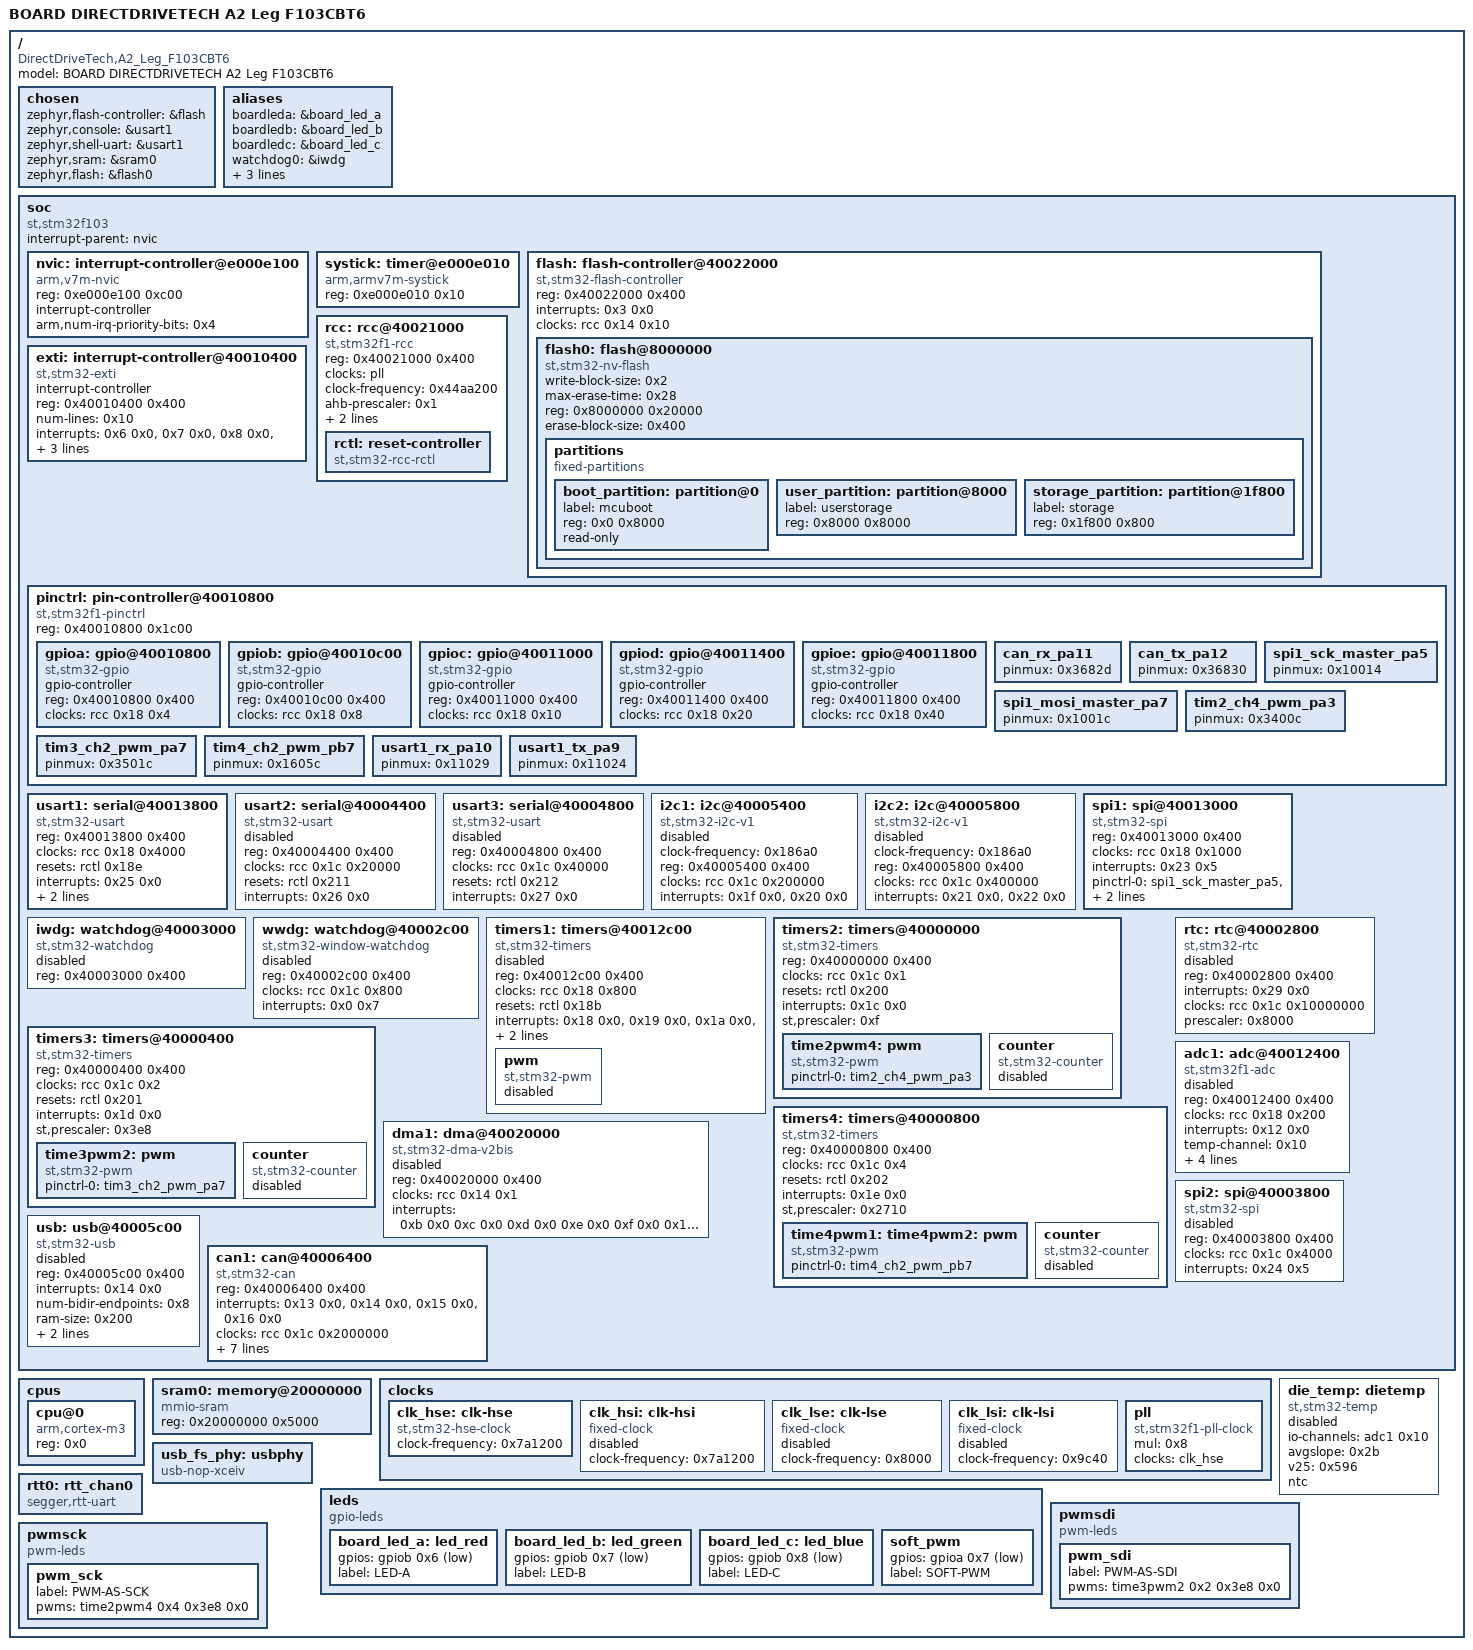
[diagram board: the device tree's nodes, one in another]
/dts-v1/;

/ {
	#address-cells = < 0x1 >;
	#size-cells = < 0x1 >;
	model = "BOARD DIRECTDRIVETECH A2 Leg F103CBT6";
	compatible = "DirectDriveTech,A2_Leg_F103CBT6";
	chosen {
		zephyr,flash-controller = &flash;
		zephyr,console = &usart1;
		zephyr,shell-uart = &usart1;
		zephyr,sram = &sram0;
		zephyr,flash = &flash0;
	};
	aliases {
		boardleda = &board_led_a;
		boardledb = &board_led_b;
		boardledc = &board_led_c;
		watchdog0 = &iwdg;
		pwmassck = &pwm_sck;
		pwmassdi = &pwm_sdi;
		softpwm = &soft_pwm;
	};
	soc {
		#address-cells = < 0x1 >;
		#size-cells = < 0x1 >;
		compatible = "st,stm32f103", "st,stm32f1", "simple-bus";
		interrupt-parent = < &nvic >;
		ranges;
		nvic: interrupt-controller@e000e100 {
			#address-cells = < 0x1 >;
			compatible = "arm,v7m-nvic";
			reg = < 0xe000e100 0xc00 >;
			interrupt-controller;
			#interrupt-cells = < 0x2 >;
			arm,num-irq-priority-bits = < 0x4 >;
			phandle = < 0x1 >;
		};
		systick: timer@e000e010 {
			compatible = "arm,armv7m-systick";
			reg = < 0xe000e010 0x10 >;
		};
		flash: flash-controller@40022000 {
			compatible = "st,stm32-flash-controller", "st,stm32f1-flash-controller";
			reg = < 0x40022000 0x400 >;
			interrupts = < 0x3 0x0 >;
			clocks = < &rcc 0x14 0x10 >;
			#address-cells = < 0x1 >;
			#size-cells = < 0x1 >;
			flash0: flash@8000000 {
				compatible = "st,stm32-nv-flash", "soc-nv-flash";
				write-block-size = < 0x2 >;
				max-erase-time = < 0x28 >;
				reg = < 0x8000000 0x20000 >;
				erase-block-size = < 0x400 >;
				partitions {
					compatible = "fixed-partitions";
					#address-cells = < 0x1 >;
					#size-cells = < 0x1 >;
					boot_partition: partition@0 {
						label = "mcuboot";
						reg = < 0x0 0x8000 >;
						read-only;
					};
					user_partition: partition@8000 {
						label = "userstorage";
						reg = < 0x8000 0x8000 >;
					};
					storage_partition: partition@1f800 {
						label = "storage";
						reg = < 0x1f800 0x800 >;
					};
				};
			};
		};
		rcc: rcc@40021000 {
			compatible = "st,stm32f1-rcc";
			#clock-cells = < 0x2 >;
			reg = < 0x40021000 0x400 >;
			clocks = < &pll >;
			clock-frequency = < 0x44aa200 >;
			ahb-prescaler = < 0x1 >;
			apb1-prescaler = < 0x2 >;
			apb2-prescaler = < 0x2 >;
			phandle = < 0x2 >;
			rctl: reset-controller {
				compatible = "st,stm32-rcc-rctl";
				#reset-cells = < 0x1 >;
				phandle = < 0x4 >;
			};
		};
		exti: interrupt-controller@40010400 {
			compatible = "st,stm32-exti";
			interrupt-controller;
			#interrupt-cells = < 0x1 >;
			#address-cells = < 0x1 >;
			reg = < 0x40010400 0x400 >;
			num-lines = < 0x10 >;
			interrupts = < 0x6 0x0 >, < 0x7 0x0 >, < 0x8 0x0 >, < 0x9 0x0 >, < 0xa 0x0 >, < 0x17 0x0 >, < 0x28 0x0 >;
			interrupt-names = "line0", "line1", "line2", "line3", "line4", "line5-9", "line10-15";
			line-ranges = < 0x0 0x1 >, < 0x1 0x1 >, < 0x2 0x1 >, < 0x3 0x1 >, < 0x4 0x1 >, < 0x5 0x5 >, < 0xa 0x6 >;
		};
		pinctrl: pin-controller@40010800 {
			compatible = "st,stm32f1-pinctrl";
			#address-cells = < 0x1 >;
			#size-cells = < 0x1 >;
			reg = < 0x40010800 0x1c00 >;
			gpioa: gpio@40010800 {
				compatible = "st,stm32-gpio";
				gpio-controller;
				#gpio-cells = < 0x2 >;
				reg = < 0x40010800 0x400 >;
				clocks = < &rcc 0x18 0x4 >;
				phandle = < 0x9 >;
			};
			gpiob: gpio@40010c00 {
				compatible = "st,stm32-gpio";
				gpio-controller;
				#gpio-cells = < 0x2 >;
				reg = < 0x40010c00 0x400 >;
				clocks = < &rcc 0x18 0x8 >;
				phandle = < 0x12 >;
			};
			gpioc: gpio@40011000 {
				compatible = "st,stm32-gpio";
				gpio-controller;
				#gpio-cells = < 0x2 >;
				reg = < 0x40011000 0x400 >;
				clocks = < &rcc 0x18 0x10 >;
			};
			gpiod: gpio@40011400 {
				compatible = "st,stm32-gpio";
				gpio-controller;
				#gpio-cells = < 0x2 >;
				reg = < 0x40011400 0x400 >;
				clocks = < &rcc 0x18 0x20 >;
			};
			gpioe: gpio@40011800 {
				compatible = "st,stm32-gpio";
				gpio-controller;
				#gpio-cells = < 0x2 >;
				reg = < 0x40011800 0x400 >;
				clocks = < &rcc 0x18 0x40 >;
			};
			can_rx_pa11: can_rx_pa11 {
				pinmux = < 0x3682d >;
				phandle = < 0xe >;
			};
			can_tx_pa12: can_tx_pa12 {
				pinmux = < 0x36830 >;
				phandle = < 0xf >;
			};
			spi1_mosi_master_pa7: spi1_mosi_master_pa7 {
				pinmux = < 0x1001c >;
				phandle = < 0x8 >;
			};
			spi1_sck_master_pa5: spi1_sck_master_pa5 {
				pinmux = < 0x10014 >;
				phandle = < 0x7 >;
			};
			tim2_ch4_pwm_pa3: tim2_ch4_pwm_pa3 {
				pinmux = < 0x3400c >;
				phandle = < 0xa >;
			};
			tim3_ch2_pwm_pa7: tim3_ch2_pwm_pa7 {
				pinmux = < 0x3501c >;
				phandle = < 0xb >;
			};
			tim4_ch2_pwm_pb7: tim4_ch2_pwm_pb7 {
				pinmux = < 0x1605c >;
				phandle = < 0xc >;
			};
			usart1_rx_pa10: usart1_rx_pa10 {
				pinmux = < 0x11029 >;
				phandle = < 0x6 >;
			};
			usart1_tx_pa9: usart1_tx_pa9 {
				pinmux = < 0x11024 >;
				phandle = < 0x5 >;
			};
		};
		usart1: serial@40013800 {
			compatible = "st,stm32-usart", "st,stm32-uart";
			reg = < 0x40013800 0x400 >;
			clocks = < &rcc 0x18 0x4000 >;
			resets = < &rctl 0x18e >;
			interrupts = < 0x25 0x0 >;
			status = "okay";
			pinctrl-0 = < &usart1_tx_pa9 &usart1_rx_pa10 >;
			pinctrl-names = "default";
			current-speed = < 0x70800 >;
		};
		usart2: serial@40004400 {
			compatible = "st,stm32-usart", "st,stm32-uart";
			reg = < 0x40004400 0x400 >;
			clocks = < &rcc 0x1c 0x20000 >;
			resets = < &rctl 0x211 >;
			interrupts = < 0x26 0x0 >;
			status = "disabled";
		};
		usart3: serial@40004800 {
			compatible = "st,stm32-usart", "st,stm32-uart";
			reg = < 0x40004800 0x400 >;
			clocks = < &rcc 0x1c 0x40000 >;
			resets = < &rctl 0x212 >;
			interrupts = < 0x27 0x0 >;
			status = "disabled";
		};
		i2c1: i2c@40005400 {
			compatible = "st,stm32-i2c-v1";
			clock-frequency = < 0x186a0 >;
			#address-cells = < 0x1 >;
			#size-cells = < 0x0 >;
			reg = < 0x40005400 0x400 >;
			clocks = < &rcc 0x1c 0x200000 >;
			interrupts = < 0x1f 0x0 >, < 0x20 0x0 >;
			interrupt-names = "event", "error";
			status = "disabled";
		};
		i2c2: i2c@40005800 {
			compatible = "st,stm32-i2c-v1";
			clock-frequency = < 0x186a0 >;
			#address-cells = < 0x1 >;
			#size-cells = < 0x0 >;
			reg = < 0x40005800 0x400 >;
			clocks = < &rcc 0x1c 0x400000 >;
			interrupts = < 0x21 0x0 >, < 0x22 0x0 >;
			interrupt-names = "event", "error";
			status = "disabled";
		};
		spi1: spi@40013000 {
			compatible = "st,stm32-spi";
			#address-cells = < 0x1 >;
			#size-cells = < 0x0 >;
			reg = < 0x40013000 0x400 >;
			clocks = < &rcc 0x18 0x1000 >;
			interrupts = < 0x23 0x5 >;
			status = "okay";
			pinctrl-0 = < &spi1_sck_master_pa5 &spi1_mosi_master_pa7 >;
			cs-gpios = < &gpioa 0x4 0x1 >;
			pinctrl-names = "default";
		};
		iwdg: watchdog@40003000 {
			compatible = "st,stm32-watchdog";
			reg = < 0x40003000 0x400 >;
			status = "disabled";
		};
		wwdg: watchdog@40002c00 {
			compatible = "st,stm32-window-watchdog";
			reg = < 0x40002c00 0x400 >;
			clocks = < &rcc 0x1c 0x800 >;
			interrupts = < 0x0 0x7 >;
			status = "disabled";
		};
		timers1: timers@40012c00 {
			compatible = "st,stm32-timers";
			reg = < 0x40012c00 0x400 >;
			clocks = < &rcc 0x18 0x800 >;
			resets = < &rctl 0x18b >;
			interrupts = < 0x18 0x0 >, < 0x19 0x0 >, < 0x1a 0x0 >, < 0x1b 0x0 >;
			interrupt-names = "brk", "up", "trgcom", "cc";
			st,prescaler = < 0x0 >;
			status = "disabled";
			pwm {
				compatible = "st,stm32-pwm";
				status = "disabled";
				#pwm-cells = < 0x3 >;
			};
		};
		timers2: timers@40000000 {
			compatible = "st,stm32-timers";
			reg = < 0x40000000 0x400 >;
			clocks = < &rcc 0x1c 0x1 >;
			resets = < &rctl 0x200 >;
			interrupts = < 0x1c 0x0 >;
			interrupt-names = "global";
			st,prescaler = < 0xf >;
			status = "okay";
			time2pwm4: pwm {
				compatible = "st,stm32-pwm";
				status = "okay";
				#pwm-cells = < 0x3 >;
				pinctrl-0 = < &tim2_ch4_pwm_pa3 >;
				pinctrl-names = "default";
				phandle = < 0x14 >;
			};
			counter {
				compatible = "st,stm32-counter";
				status = "disabled";
			};
		};
		timers3: timers@40000400 {
			compatible = "st,stm32-timers";
			reg = < 0x40000400 0x400 >;
			clocks = < &rcc 0x1c 0x2 >;
			resets = < &rctl 0x201 >;
			interrupts = < 0x1d 0x0 >;
			interrupt-names = "global";
			st,prescaler = < 0x3e8 >;
			status = "okay";
			time3pwm2: pwm {
				compatible = "st,stm32-pwm";
				status = "okay";
				#pwm-cells = < 0x3 >;
				pinctrl-0 = < &tim3_ch2_pwm_pa7 >;
				pinctrl-names = "default";
				phandle = < 0x13 >;
			};
			counter {
				compatible = "st,stm32-counter";
				status = "disabled";
			};
		};
		timers4: timers@40000800 {
			compatible = "st,stm32-timers";
			reg = < 0x40000800 0x400 >;
			clocks = < &rcc 0x1c 0x4 >;
			resets = < &rctl 0x202 >;
			interrupts = < 0x1e 0x0 >;
			interrupt-names = "global";
			st,prescaler = < 0x2710 >;
			status = "okay";
			time4pwm1: time4pwm2: pwm {
				compatible = "st,stm32-pwm";
				status = "okay";
				#pwm-cells = < 0x3 >;
				pinctrl-0 = < &tim4_ch2_pwm_pb7 >;
				pinctrl-names = "default";
			};
			counter {
				compatible = "st,stm32-counter";
				status = "disabled";
			};
		};
		rtc: rtc@40002800 {
			compatible = "st,stm32-rtc";
			reg = < 0x40002800 0x400 >;
			interrupts = < 0x29 0x0 >;
			clocks = < &rcc 0x1c 0x10000000 >;
			prescaler = < 0x8000 >;
			status = "disabled";
		};
		adc1: adc@40012400 {
			compatible = "st,stm32f1-adc", "st,stm32-adc";
			reg = < 0x40012400 0x400 >;
			clocks = < &rcc 0x18 0x200 >;
			interrupts = < 0x12 0x0 >;
			status = "disabled";
			#io-channel-cells = < 0x1 >;
			temp-channel = < 0x10 >;
			vref-channel = < 0x11 >;
			resolutions = < 0x6000ff >;
			sampling-times = < 0x2 0x8 0xe 0x1d 0x2a 0x38 0x48 0xf0 >;
			phandle = < 0x11 >;
		};
		dma1: dma@40020000 {
			compatible = "st,stm32-dma-v2bis";
			#dma-cells = < 0x2 >;
			reg = < 0x40020000 0x400 >;
			clocks = < &rcc 0x14 0x1 >;
			interrupts = < 0xb 0x0 0xc 0x0 0xd 0x0 0xe 0x0 0xf 0x0 0x10 0x0 0x11 0x0 >;
			status = "disabled";
		};
		spi2: spi@40003800 {
			compatible = "st,stm32-spi";
			#address-cells = < 0x1 >;
			#size-cells = < 0x0 >;
			reg = < 0x40003800 0x400 >;
			clocks = < &rcc 0x1c 0x4000 >;
			interrupts = < 0x24 0x5 >;
			status = "disabled";
		};
		usb: usb@40005c00 {
			compatible = "st,stm32-usb";
			reg = < 0x40005c00 0x400 >;
			interrupts = < 0x14 0x0 >;
			interrupt-names = "usb";
			num-bidir-endpoints = < 0x8 >;
			ram-size = < 0x200 >;
			status = "disabled";
			clocks = < &rcc 0x1c 0x800000 >;
			phys = < &usb_fs_phy >;
		};
		can1: can@40006400 {
			compatible = "st,stm32-can";
			reg = < 0x40006400 0x400 >;
			interrupts = < 0x13 0x0 >, < 0x14 0x0 >, < 0x15 0x0 >, < 0x16 0x0 >;
			interrupt-names = "TX", "RX0", "RX1", "SCE";
			clocks = < &rcc 0x1c 0x2000000 >;
			status = "okay";
			sjw = < 0x1 >;
			sample-point = < 0x36b >;
			pinctrl-0 = < &can_rx_pa11 &can_tx_pa12 >;
			pinctrl-names = "default";
			bus-speed = < 0xf4240 >;
			prop-seg = < 0x0 >;
			phase-seg1 = < 0x4 >;
			phase-seg2 = < 0x2 >;
		};
	};
	cpus {
		#address-cells = < 0x1 >;
		#size-cells = < 0x0 >;
		cpu@0 {
			device_type = "cpu";
			compatible = "arm,cortex-m3";
			reg = < 0x0 >;
		};
	};
	sram0: memory@20000000 {
		compatible = "mmio-sram";
		reg = < 0x20000000 0x5000 >;
	};
	clocks {
		clk_hse: clk-hse {
			#clock-cells = < 0x0 >;
			compatible = "st,stm32-hse-clock";
			status = "okay";
			clock-frequency = < 0x7a1200 >;
			phandle = < 0x10 >;
		};
		clk_hsi: clk-hsi {
			#clock-cells = < 0x0 >;
			compatible = "fixed-clock";
			clock-frequency = < 0x7a1200 >;
			status = "disabled";
		};
		clk_lse: clk-lse {
			#clock-cells = < 0x0 >;
			compatible = "fixed-clock";
			clock-frequency = < 0x8000 >;
			status = "disabled";
		};
		clk_lsi: clk-lsi {
			#clock-cells = < 0x0 >;
			compatible = "fixed-clock";
			clock-frequency = < 0x9c40 >;
			status = "disabled";
		};
		pll: pll {
			#clock-cells = < 0x0 >;
			compatible = "st,stm32f1-pll-clock";
			status = "okay";
			mul = < 0x8 >;
			clocks = < &clk_hse >;
			phandle = < 0x3 >;
		};
	};
	die_temp: dietemp {
		compatible = "st,stm32-temp";
		io-channels = < &adc1 0x10 >;
		status = "disabled";
		avgslope = < 0x2b >;
		v25 = < 0x596 >;
		ntc;
	};
	usb_fs_phy: usbphy {
		compatible = "usb-nop-xceiv";
		#phy-cells = < 0x0 >;
		phandle = < 0xd >;
	};
	rtt0: rtt_chan0 {
		compatible = "segger,rtt-uart";
		status = "okay";
	};
	leds {
		compatible = "gpio-leds";
		board_led_a: led_red {
			gpios = < &gpiob 0x6 0x1 >;
			label = "LED-A";
		};
		board_led_b: led_green {
			gpios = < &gpiob 0x7 0x1 >;
			label = "LED-B";
		};
		board_led_c: led_blue {
			gpios = < &gpiob 0x8 0x1 >;
			label = "LED-C";
		};
		soft_pwm: soft_pwm {
			gpios = < &gpioa 0x7 0x1 >;
			label = "SOFT-PWM";
		};
	};
	pwmsdi {
		compatible = "pwm-leds";
		status = "okay";
		pwm_sdi: pwm_sdi {
			label = "PWM-AS-SDI";
			pwms = < &time3pwm2 0x2 0x3e8 0x0 >;
		};
	};
	pwmsck {
		compatible = "pwm-leds";
		status = "okay";
		pwm_sck: pwm_sck {
			label = "PWM-AS-SCK";
			pwms = < &time2pwm4 0x4 0x3e8 0x0 >;
		};
	};
};
